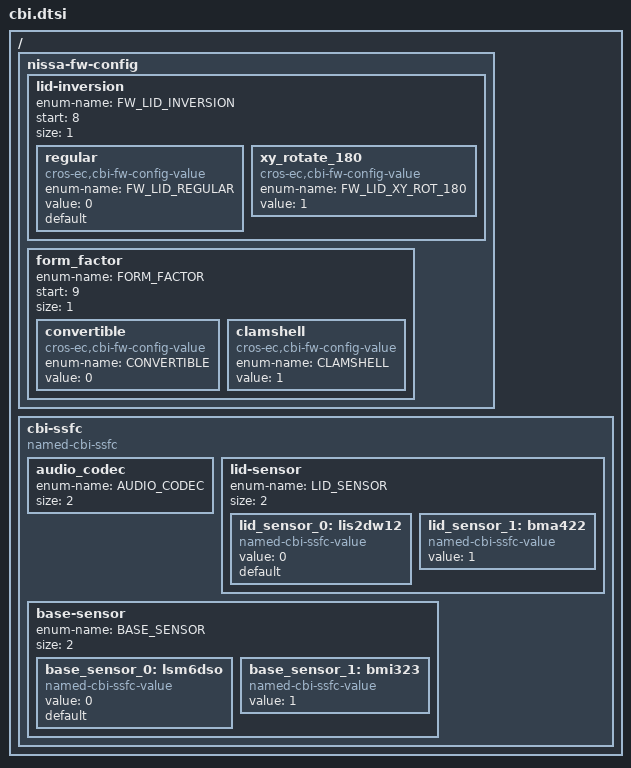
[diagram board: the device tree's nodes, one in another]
/* Copyright 2022 The ChromiumOS Authors
 * Use of this source code is governed by a BSD-style license that can be
 * found in the LICENSE file.
 */

/ {
	/* Craask-specific fw_config fields. */
	nissa-fw-config {
		/*
		 * FW_CONFIG field to describe Lid sensor orientation.
		 */
		lid-inversion {
			enum-name = "FW_LID_INVERSION";
			start = <8>;
			size = <1>;

			/*
			 * 0: regular placement of the lid sensor
			 * 1: rotate 180' of xy plane.
			 */
			regular {
				compatible = "cros-ec,cbi-fw-config-value";
				enum-name = "FW_LID_REGULAR";
				value = <0>;
				default;
			};
			xy_rotate_180 {
				compatible = "cros-ec,cbi-fw-config-value";
				enum-name = "FW_LID_XY_ROT_180";
				value = <1>;
			};
		};
		/*
		 * FW_CONFIG field to describe Clamshell/Convertible.
		 */
		form_factor {
			enum-name = "FORM_FACTOR";
			start = <9>;
			size = <1>;

			/*
			 * 0: convertible, 1: clamshell
			 */
			convertible {
				compatible = "cros-ec,cbi-fw-config-value";
				enum-name = "CONVERTIBLE";
				value = <0>;
			};
			clamshell {
				compatible = "cros-ec,cbi-fw-config-value";
				enum-name = "CLAMSHELL";
				value = <1>;
			};
		};
	};
	/* Craask-specific ssfc fields. */
	cbi-ssfc {
		compatible = "named-cbi-ssfc";
		/*
		 * SSFC bit0-1 was defined for AUDIO CODEC.
		 * 0: ALC5682I_VS
		 * 1: NAU8825
		 */
		audio_codec {
			enum-name = "AUDIO_CODEC";
			size = <2>;
		};
		/*
		 * SSFC field to identify LID motion sensor.
		 */
		lid-sensor {
			enum-name = "LID_SENSOR";
			size = <2>;

			lid_sensor_0: lis2dw12 {
				compatible = "named-cbi-ssfc-value";
				status = "okay";
				value = <0>;
				default;
			};
			lid_sensor_1: bma422 {
				compatible = "named-cbi-ssfc-value";
				status = "okay";
				value = <1>;
			};
		};
		/*
		 * SSFC field to identify BASE motion sensor.
		 */
		base-sensor {
			enum-name = "BASE_SENSOR";
			size = <2>;

			base_sensor_0: lsm6dso {
				compatible = "named-cbi-ssfc-value";
				status = "okay";
				value = <0>;
				default;
			};
			base_sensor_1: bmi323 {
				compatible = "named-cbi-ssfc-value";
				status = "okay";
				value = <1>;
			};
		};
	};
};
